# ECC_AGGR_ECC_AGGR_04703000h register map
Vendor: Texas Instruments
Peripheral module from a debugger description file (folder am62D).
Registers are 32-bit, access not given, reset 0x0 unless marked. A register's access mark holds for its fields unless they carry their own. Offsets are as the file gives them; lines under a group give offsets from that group; [hi:lo] are bit positions; {n}, {i} and the like mark numbered series; 'fields as' and 'values as' point back to an identical list; <NAME> marks a mode.

## ecc_aggr
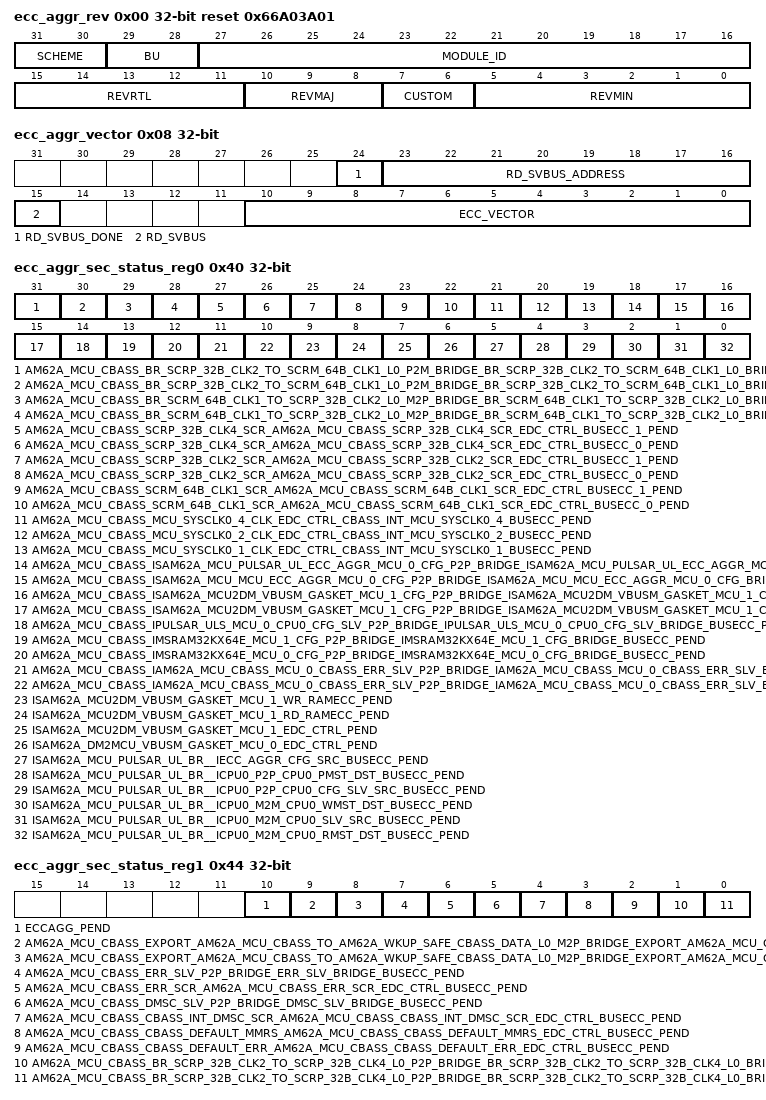
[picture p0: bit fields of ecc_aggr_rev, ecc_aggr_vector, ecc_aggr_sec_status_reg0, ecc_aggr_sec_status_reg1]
0x00 ecc_aggr_rev ro reset 0x66A03A01 — Revision parameters
  [31:30] SCHEME
  [29:28] BU
  [27:16] MODULE_ID
  [15:11] REVRTL — RTL version
  [10:8] REVMAJ — Major version
  [7:6] CUSTOM — Custom version
  [5:0] REVMIN — Minor version
0x08 ecc_aggr_vector — ECC Vector Register
  [24] RD_SVBUS_DONE — Status to indicate if read on serial VBUS is complete, write of any value will clear this bit. (access R/W1TC)
  [23:16] RD_SVBUS_ADDRESS rw — Read address
  [15] RD_SVBUS — Write 1 to trigger a read on the serial VBUS (access R/W1TS)
  [10:0] ECC_VECTOR rw — Value written to select the corresponding ECC RAM for control or status
0x0C ecc_aggr_stat ro reset 0x2B — Misc Status
  [10:0] NUM_RAMS — Indicates the number of RAMS serviced by the ECC aggregator
0x10 ecc_aggr_reserved_svbus_j rw — Reference other documents that contain the ECC RAM wrapper and EDC controller serial vbus register sets.
  [31:0] DATA — Serial VBUS register data
0x3C ecc_aggr_sec_eoi_reg — EOI Register
  [0] EOI_WR — EOI Register (access R/W1TS)
0x40 ecc_aggr_sec_status_reg0 — Interrupt Status Register 0
  [31] AM62A_MCU_CBASS_BR_SCRP_32B_CLK2_TO_SCRM_64B_CLK1_L0_P2M_BRIDGE_BR_SCRP_32B_CLK2_TO_SCRM_64B_CLK1_L0_BRIDGE_SRC_BUSECC_PEND — Interrupt Pending Status for am62a_mcu_cbass_br_SCRP_32b_clk2_to_SCRM_64b_clk1_l0_p2m_bridge_br_SCRP_32b_clk2_to_SCRM_64b_clk1_l0_bridge_src_busecc_pend (access R/W1TS)
  [30] AM62A_MCU_CBASS_BR_SCRP_32B_CLK2_TO_SCRM_64B_CLK1_L0_P2M_BRIDGE_BR_SCRP_32B_CLK2_TO_SCRM_64B_CLK1_L0_BRIDGE_DST_BUSECC_PEND — Interrupt Pending Status for am62a_mcu_cbass_br_SCRP_32b_clk2_to_SCRM_64b_clk1_l0_p2m_bridge_br_SCRP_32b_clk2_to_SCRM_64b_clk1_l0_bridge_dst_busecc_pend (access R/W1TS)
  [29] AM62A_MCU_CBASS_BR_SCRM_64B_CLK1_TO_SCRP_32B_CLK2_L0_M2P_BRIDGE_BR_SCRM_64B_CLK1_TO_SCRP_32B_CLK2_L0_BRIDGE_SRC_BUSECC_PEND — Interrupt Pending Status for am62a_mcu_cbass_br_SCRM_64b_clk1_to_SCRP_32b_clk2_l0_m2p_bridge_br_SCRM_64b_clk1_to_SCRP_32b_clk2_l0_bridge_src_busecc_pend (access R/W1TS)
  [28] AM62A_MCU_CBASS_BR_SCRM_64B_CLK1_TO_SCRP_32B_CLK2_L0_M2P_BRIDGE_BR_SCRM_64B_CLK1_TO_SCRP_32B_CLK2_L0_BRIDGE_DST_BUSECC_PEND — Interrupt Pending Status for am62a_mcu_cbass_br_SCRM_64b_clk1_to_SCRP_32b_clk2_l0_m2p_bridge_br_SCRM_64b_clk1_to_SCRP_32b_clk2_l0_bridge_dst_busecc_pend (access R/W1TS)
  [27] AM62A_MCU_CBASS_SCRP_32B_CLK4_SCR_AM62A_MCU_CBASS_SCRP_32B_CLK4_SCR_EDC_CTRL_BUSECC_1_PEND — Interrupt Pending Status for am62a_mcu_cbass_SCRP_32b_clk4_scr_am62a_mcu_cbass_SCRP_32b_clk4_scr_edc_ctrl_busecc_1_pend (access R/W1TS)
  [26] AM62A_MCU_CBASS_SCRP_32B_CLK4_SCR_AM62A_MCU_CBASS_SCRP_32B_CLK4_SCR_EDC_CTRL_BUSECC_0_PEND — Interrupt Pending Status for am62a_mcu_cbass_SCRP_32b_clk4_scr_am62a_mcu_cbass_SCRP_32b_clk4_scr_edc_ctrl_busecc_0_pend (access R/W1TS)
  [25] AM62A_MCU_CBASS_SCRP_32B_CLK2_SCR_AM62A_MCU_CBASS_SCRP_32B_CLK2_SCR_EDC_CTRL_BUSECC_1_PEND — Interrupt Pending Status for am62a_mcu_cbass_SCRP_32b_clk2_scr_am62a_mcu_cbass_SCRP_32b_clk2_scr_edc_ctrl_busecc_1_pend (access R/W1TS)
  [24] AM62A_MCU_CBASS_SCRP_32B_CLK2_SCR_AM62A_MCU_CBASS_SCRP_32B_CLK2_SCR_EDC_CTRL_BUSECC_0_PEND — Interrupt Pending Status for am62a_mcu_cbass_SCRP_32b_clk2_scr_am62a_mcu_cbass_SCRP_32b_clk2_scr_edc_ctrl_busecc_0_pend (access R/W1TS)
  [23] AM62A_MCU_CBASS_SCRM_64B_CLK1_SCR_AM62A_MCU_CBASS_SCRM_64B_CLK1_SCR_EDC_CTRL_BUSECC_1_PEND — Interrupt Pending Status for am62a_mcu_cbass_SCRM_64b_clk1_scr_am62a_mcu_cbass_SCRM_64b_clk1_scr_edc_ctrl_busecc_1_pend (access R/W1TS)
  [22] AM62A_MCU_CBASS_SCRM_64B_CLK1_SCR_AM62A_MCU_CBASS_SCRM_64B_CLK1_SCR_EDC_CTRL_BUSECC_0_PEND — Interrupt Pending Status for am62a_mcu_cbass_SCRM_64b_clk1_scr_am62a_mcu_cbass_SCRM_64b_clk1_scr_edc_ctrl_busecc_0_pend (access R/W1TS)
  [21] AM62A_MCU_CBASS_MCU_SYSCLK0_4_CLK_EDC_CTRL_CBASS_INT_MCU_SYSCLK0_4_BUSECC_PEND — Interrupt Pending Status for am62a_mcu_cbass_MCU_SYSCLK0_4_clk_edc_ctrl_cbass_int_MCU_SYSCLK0_4_busecc_pend (access R/W1TS)
  [20] AM62A_MCU_CBASS_MCU_SYSCLK0_2_CLK_EDC_CTRL_CBASS_INT_MCU_SYSCLK0_2_BUSECC_PEND — Interrupt Pending Status for am62a_mcu_cbass_MCU_SYSCLK0_2_clk_edc_ctrl_cbass_int_MCU_SYSCLK0_2_busecc_pend (access R/W1TS)
  [19] AM62A_MCU_CBASS_MCU_SYSCLK0_1_CLK_EDC_CTRL_CBASS_INT_MCU_SYSCLK0_1_BUSECC_PEND — Interrupt Pending Status for am62a_mcu_cbass_MCU_SYSCLK0_1_clk_edc_ctrl_cbass_int_MCU_SYSCLK0_1_busecc_pend (access R/W1TS)
  [18] AM62A_MCU_CBASS_ISAM62A_MCU_PULSAR_UL_ECC_AGGR_MCU_0_CFG_P2P_BRIDGE_ISAM62A_MCU_PULSAR_UL_ECC_AGGR_MCU_0_CFG_BRIDGE_BUSECC_PEND — Interrupt Pending Status for am62a_mcu_cbass_Isam62a_mcu_pulsar_ul_ecc_aggr_mcu_0_cfg_p2p_bridge_Isam62a_mcu_pulsar_ul_ecc_aggr_mcu_0_cfg_bridge_busecc_pend (access R/W1TS)
  [17] AM62A_MCU_CBASS_ISAM62A_MCU_MCU_ECC_AGGR_MCU_0_CFG_P2P_BRIDGE_ISAM62A_MCU_MCU_ECC_AGGR_MCU_0_CFG_BRIDGE_BUSECC_PEND — Interrupt Pending Status for am62a_mcu_cbass_Isam62a_mcu_mcu_ecc_aggr_mcu_0_cfg_p2p_bridge_Isam62a_mcu_mcu_ecc_aggr_mcu_0_cfg_bridge_busecc_pend (access R/W1TS)
  [16] AM62A_MCU_CBASS_ISAM62A_MCU2DM_VBUSM_GASKET_MCU_1_CFG_P2P_BRIDGE_ISAM62A_MCU2DM_VBUSM_GASKET_MCU_1_CFG_BRIDGE_SRC_BUSECC_PEND — Interrupt Pending Status for am62a_mcu_cbass_Isam62a_mcu2dm_vbusm_gasket_mcu_1_cfg_p2p_bridge_Isam62a_mcu2dm_vbusm_gasket_mcu_1_cfg_bridge_src_busecc_pend (access R/W1TS)
  [15] AM62A_MCU_CBASS_ISAM62A_MCU2DM_VBUSM_GASKET_MCU_1_CFG_P2P_BRIDGE_ISAM62A_MCU2DM_VBUSM_GASKET_MCU_1_CFG_BRIDGE_DST_BUSECC_PEND — Interrupt Pending Status for am62a_mcu_cbass_Isam62a_mcu2dm_vbusm_gasket_mcu_1_cfg_p2p_bridge_Isam62a_mcu2dm_vbusm_gasket_mcu_1_cfg_bridge_dst_busecc_pend (access R/W1TS)
  [14] AM62A_MCU_CBASS_IPULSAR_ULS_MCU_0_CPU0_CFG_SLV_P2P_BRIDGE_IPULSAR_ULS_MCU_0_CPU0_CFG_SLV_BRIDGE_BUSECC_PEND — Interrupt Pending Status for am62a_mcu_cbass_Ipulsar_uls_mcu_0_cpu0_cfg_slv_p2p_bridge_Ipulsar_uls_mcu_0_cpu0_cfg_slv_bridge_busecc_pend (access R/W1TS)
  [13] AM62A_MCU_CBASS_IMSRAM32KX64E_MCU_1_CFG_P2P_BRIDGE_IMSRAM32KX64E_MCU_1_CFG_BRIDGE_BUSECC_PEND — Interrupt Pending Status for am62a_mcu_cbass_Imsram32kx64e_mcu_1_cfg_p2p_bridge_Imsram32kx64e_mcu_1_cfg_bridge_busecc_pend (access R/W1TS)
  [12] AM62A_MCU_CBASS_IMSRAM32KX64E_MCU_0_CFG_P2P_BRIDGE_IMSRAM32KX64E_MCU_0_CFG_BRIDGE_BUSECC_PEND — Interrupt Pending Status for am62a_mcu_cbass_Imsram32kx64e_mcu_0_cfg_p2p_bridge_Imsram32kx64e_mcu_0_cfg_bridge_busecc_pend (access R/W1TS)
  [11] AM62A_MCU_CBASS_IAM62A_MCU_CBASS_MCU_0_CBASS_ERR_SLV_P2P_BRIDGE_IAM62A_MCU_CBASS_MCU_0_CBASS_ERR_SLV_BRIDGE_SRC_BUSECC_PEND — Interrupt Pending Status for am62a_mcu_cbass_Iam62a_mcu_cbass_mcu_0_cbass_err_slv_p2p_bridge_Iam62a_mcu_cbass_mcu_0_cbass_err_slv_bridge_src_busecc_pend (access R/W1TS)
  [10] AM62A_MCU_CBASS_IAM62A_MCU_CBASS_MCU_0_CBASS_ERR_SLV_P2P_BRIDGE_IAM62A_MCU_CBASS_MCU_0_CBASS_ERR_SLV_BRIDGE_DST_BUSECC_PEND — Interrupt Pending Status for am62a_mcu_cbass_Iam62a_mcu_cbass_mcu_0_cbass_err_slv_p2p_bridge_Iam62a_mcu_cbass_mcu_0_cbass_err_slv_bridge_dst_busecc_pend (access R/W1TS)
  [9] ISAM62A_MCU2DM_VBUSM_GASKET_MCU_1_WR_RAMECC_PEND — Interrupt Pending Status for Isam62a_mcu2dm_vbusm_gasket_mcu_1_wr_ramecc_pend (access R/W1TS)
  [8] ISAM62A_MCU2DM_VBUSM_GASKET_MCU_1_RD_RAMECC_PEND — Interrupt Pending Status for Isam62a_mcu2dm_vbusm_gasket_mcu_1_rd_ramecc_pend (access R/W1TS)
  [7] ISAM62A_MCU2DM_VBUSM_GASKET_MCU_1_EDC_CTRL_PEND — Interrupt Pending Status for Isam62a_mcu2dm_vbusm_gasket_mcu_1_edc_ctrl_pend (access R/W1TS)
  [6] ISAM62A_DM2MCU_VBUSM_GASKET_MCU_0_EDC_CTRL_PEND — Interrupt Pending Status for Isam62a_dm2mcu_vbusm_gasket_mcu_0_edc_ctrl_pend (access R/W1TS)
  [5] ISAM62A_MCU_PULSAR_UL_BR__IECC_AGGR_CFG_SRC_BUSECC_PEND — Interrupt Pending Status for Isam62a_mcu_pulsar_ul_br__Iecc_aggr_cfg_src_busecc_pend (access R/W1TS)
  [4] ISAM62A_MCU_PULSAR_UL_BR__ICPU0_P2P_CPU0_PMST_DST_BUSECC_PEND — Interrupt Pending Status for Isam62a_mcu_pulsar_ul_br__Icpu0_p2p_cpu0_pmst_dst_busecc_pend (access R/W1TS)
  [3] ISAM62A_MCU_PULSAR_UL_BR__ICPU0_P2P_CPU0_CFG_SLV_SRC_BUSECC_PEND — Interrupt Pending Status for Isam62a_mcu_pulsar_ul_br__Icpu0_p2p_cpu0_cfg_slv_src_busecc_pend (access R/W1TS)
  [2] ISAM62A_MCU_PULSAR_UL_BR__ICPU0_M2M_CPU0_WMST_DST_BUSECC_PEND — Interrupt Pending Status for Isam62a_mcu_pulsar_ul_br__Icpu0_m2m_cpu0_wmst_dst_busecc_pend (access R/W1TS)
  [1] ISAM62A_MCU_PULSAR_UL_BR__ICPU0_M2M_CPU0_SLV_SRC_BUSECC_PEND — Interrupt Pending Status for Isam62a_mcu_pulsar_ul_br__Icpu0_m2m_cpu0_slv_src_busecc_pend (access R/W1TS)
  [0] ISAM62A_MCU_PULSAR_UL_BR__ICPU0_M2M_CPU0_RMST_DST_BUSECC_PEND — Interrupt Pending Status for Isam62a_mcu_pulsar_ul_br__Icpu0_m2m_cpu0_rmst_dst_busecc_pend (access R/W1TS)
0x44 ecc_aggr_sec_status_reg1 — Interrupt Status Register 1
  [10] ECCAGG_PEND — Interrupt Pending Status for eccagg_pend (access R/W1TS)
  [9] AM62A_MCU_CBASS_EXPORT_AM62A_MCU_CBASS_TO_AM62A_WKUP_SAFE_CBASS_DATA_L0_M2P_BRIDGE_EXPORT_AM62A_MCU_CBASS_TO_AM62A_WKUP_SAFE_CBASS_DATA_L0_BRIDGE_SRC_BUSECC_PEND — Interrupt Pending Status for am62a_mcu_cbass_export_am62a_mcu_cbass_to_am62a_wkup_safe_cbass_data_l0_m2p_bridge_export_am62a_mcu_cbass_to_am62a_wkup_safe_cbass_data_l0_bridge_src_busecc_pend (access R/W1TS)
  [8] AM62A_MCU_CBASS_EXPORT_AM62A_MCU_CBASS_TO_AM62A_WKUP_SAFE_CBASS_DATA_L0_M2P_BRIDGE_EXPORT_AM62A_MCU_CBASS_TO_AM62A_WKUP_SAFE_CBASS_DATA_L0_BRIDGE_DST_BUSECC_PEND — Interrupt Pending Status for am62a_mcu_cbass_export_am62a_mcu_cbass_to_am62a_wkup_safe_cbass_data_l0_m2p_bridge_export_am62a_mcu_cbass_to_am62a_wkup_safe_cbass_data_l0_bridge_dst_busecc_pend (access R/W1TS)
  [7] AM62A_MCU_CBASS_ERR_SLV_P2P_BRIDGE_ERR_SLV_BRIDGE_BUSECC_PEND — Interrupt Pending Status for am62a_mcu_cbass_err_slv_p2p_bridge_err_slv_bridge_busecc_pend (access R/W1TS)
  [6] AM62A_MCU_CBASS_ERR_SCR_AM62A_MCU_CBASS_ERR_SCR_EDC_CTRL_BUSECC_PEND — Interrupt Pending Status for am62a_mcu_cbass_err_scr_am62a_mcu_cbass_err_scr_edc_ctrl_busecc_pend (access R/W1TS)
  [5] AM62A_MCU_CBASS_DMSC_SLV_P2P_BRIDGE_DMSC_SLV_BRIDGE_BUSECC_PEND — Interrupt Pending Status for am62a_mcu_cbass_dmsc_slv_p2p_bridge_dmsc_slv_bridge_busecc_pend (access R/W1TS)
  [4] AM62A_MCU_CBASS_CBASS_INT_DMSC_SCR_AM62A_MCU_CBASS_CBASS_INT_DMSC_SCR_EDC_CTRL_BUSECC_PEND — Interrupt Pending Status for am62a_mcu_cbass_cbass_int_dmsc_scr_am62a_mcu_cbass_cbass_int_dmsc_scr_edc_ctrl_busecc_pend (access R/W1TS)
  [3] AM62A_MCU_CBASS_CBASS_DEFAULT_MMRS_AM62A_MCU_CBASS_CBASS_DEFAULT_MMRS_EDC_CTRL_BUSECC_PEND — Interrupt Pending Status for am62a_mcu_cbass_cbass_default_mmrs_am62a_mcu_cbass_cbass_default_mmrs_edc_ctrl_busecc_pend (access R/W1TS)
  [2] AM62A_MCU_CBASS_CBASS_DEFAULT_ERR_AM62A_MCU_CBASS_CBASS_DEFAULT_ERR_EDC_CTRL_BUSECC_PEND — Interrupt Pending Status for am62a_mcu_cbass_cbass_default_err_am62a_mcu_cbass_cbass_default_err_edc_ctrl_busecc_pend (access R/W1TS)
  [1] AM62A_MCU_CBASS_BR_SCRP_32B_CLK2_TO_SCRP_32B_CLK4_L0_P2P_BRIDGE_BR_SCRP_32B_CLK2_TO_SCRP_32B_CLK4_L0_BRIDGE_SRC_BUSECC_PEND — Interrupt Pending Status for am62a_mcu_cbass_br_SCRP_32b_clk2_to_SCRP_32b_clk4_l0_p2p_bridge_br_SCRP_32b_clk2_to_SCRP_32b_clk4_l0_bridge_src_busecc_pend (access R/W1TS)
  [0] AM62A_MCU_CBASS_BR_SCRP_32B_CLK2_TO_SCRP_32B_CLK4_L0_P2P_BRIDGE_BR_SCRP_32B_CLK2_TO_SCRP_32B_CLK4_L0_BRIDGE_DST_BUSECC_PEND — Interrupt Pending Status for am62a_mcu_cbass_br_SCRP_32b_clk2_to_SCRP_32b_clk4_l0_p2p_bridge_br_SCRP_32b_clk2_to_SCRP_32b_clk4_l0_bridge_dst_busecc_pend (access R/W1TS)
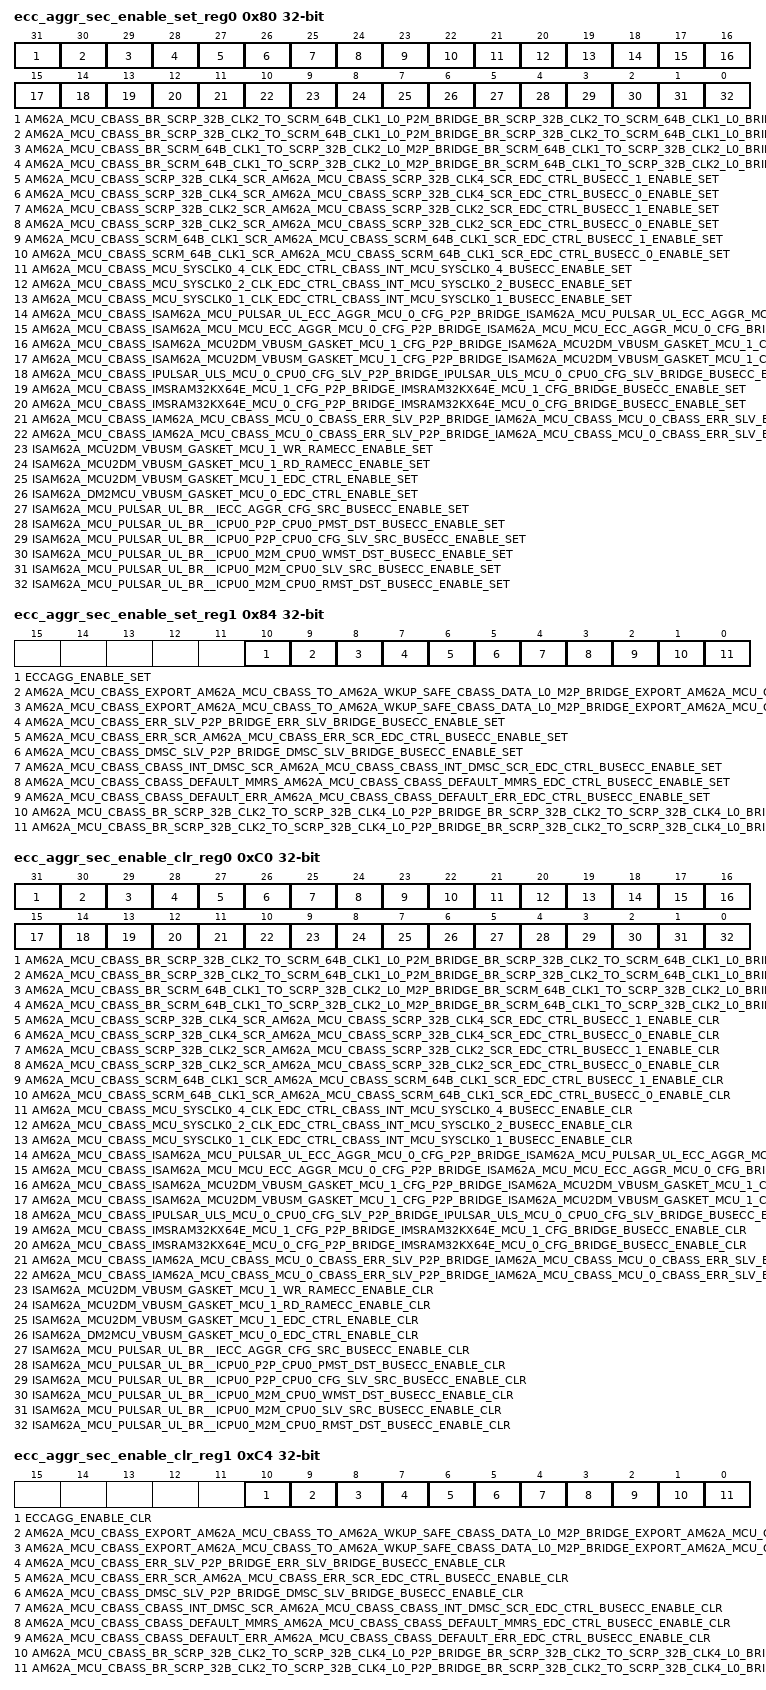
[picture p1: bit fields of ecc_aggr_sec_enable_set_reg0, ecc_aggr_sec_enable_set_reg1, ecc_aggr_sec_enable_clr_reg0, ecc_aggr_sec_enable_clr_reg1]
0x80 ecc_aggr_sec_enable_set_reg0 — Interrupt Enable Set Register 0
  [31] AM62A_MCU_CBASS_BR_SCRP_32B_CLK2_TO_SCRM_64B_CLK1_L0_P2M_BRIDGE_BR_SCRP_32B_CLK2_TO_SCRM_64B_CLK1_L0_BRIDGE_SRC_BUSECC_ENABLE_SET — Interrupt Enable Set Register for am62a_mcu_cbass_br_SCRP_32b_clk2_to_SCRM_64b_clk1_l0_p2m_bridge_br_SCRP_32b_clk2_to_SCRM_64b_clk1_l0_bridge_src_busecc_pend (access R/W1TS)
  [30] AM62A_MCU_CBASS_BR_SCRP_32B_CLK2_TO_SCRM_64B_CLK1_L0_P2M_BRIDGE_BR_SCRP_32B_CLK2_TO_SCRM_64B_CLK1_L0_BRIDGE_DST_BUSECC_ENABLE_SET — Interrupt Enable Set Register for am62a_mcu_cbass_br_SCRP_32b_clk2_to_SCRM_64b_clk1_l0_p2m_bridge_br_SCRP_32b_clk2_to_SCRM_64b_clk1_l0_bridge_dst_busecc_pend (access R/W1TS)
  [29] AM62A_MCU_CBASS_BR_SCRM_64B_CLK1_TO_SCRP_32B_CLK2_L0_M2P_BRIDGE_BR_SCRM_64B_CLK1_TO_SCRP_32B_CLK2_L0_BRIDGE_SRC_BUSECC_ENABLE_SET — Interrupt Enable Set Register for am62a_mcu_cbass_br_SCRM_64b_clk1_to_SCRP_32b_clk2_l0_m2p_bridge_br_SCRM_64b_clk1_to_SCRP_32b_clk2_l0_bridge_src_busecc_pend (access R/W1TS)
  [28] AM62A_MCU_CBASS_BR_SCRM_64B_CLK1_TO_SCRP_32B_CLK2_L0_M2P_BRIDGE_BR_SCRM_64B_CLK1_TO_SCRP_32B_CLK2_L0_BRIDGE_DST_BUSECC_ENABLE_SET — Interrupt Enable Set Register for am62a_mcu_cbass_br_SCRM_64b_clk1_to_SCRP_32b_clk2_l0_m2p_bridge_br_SCRM_64b_clk1_to_SCRP_32b_clk2_l0_bridge_dst_busecc_pend (access R/W1TS)
  [27] AM62A_MCU_CBASS_SCRP_32B_CLK4_SCR_AM62A_MCU_CBASS_SCRP_32B_CLK4_SCR_EDC_CTRL_BUSECC_1_ENABLE_SET — Interrupt Enable Set Register for am62a_mcu_cbass_SCRP_32b_clk4_scr_am62a_mcu_cbass_SCRP_32b_clk4_scr_edc_ctrl_busecc_1_pend (access R/W1TS)
  [26] AM62A_MCU_CBASS_SCRP_32B_CLK4_SCR_AM62A_MCU_CBASS_SCRP_32B_CLK4_SCR_EDC_CTRL_BUSECC_0_ENABLE_SET — Interrupt Enable Set Register for am62a_mcu_cbass_SCRP_32b_clk4_scr_am62a_mcu_cbass_SCRP_32b_clk4_scr_edc_ctrl_busecc_0_pend (access R/W1TS)
  [25] AM62A_MCU_CBASS_SCRP_32B_CLK2_SCR_AM62A_MCU_CBASS_SCRP_32B_CLK2_SCR_EDC_CTRL_BUSECC_1_ENABLE_SET — Interrupt Enable Set Register for am62a_mcu_cbass_SCRP_32b_clk2_scr_am62a_mcu_cbass_SCRP_32b_clk2_scr_edc_ctrl_busecc_1_pend (access R/W1TS)
  [24] AM62A_MCU_CBASS_SCRP_32B_CLK2_SCR_AM62A_MCU_CBASS_SCRP_32B_CLK2_SCR_EDC_CTRL_BUSECC_0_ENABLE_SET — Interrupt Enable Set Register for am62a_mcu_cbass_SCRP_32b_clk2_scr_am62a_mcu_cbass_SCRP_32b_clk2_scr_edc_ctrl_busecc_0_pend (access R/W1TS)
  [23] AM62A_MCU_CBASS_SCRM_64B_CLK1_SCR_AM62A_MCU_CBASS_SCRM_64B_CLK1_SCR_EDC_CTRL_BUSECC_1_ENABLE_SET — Interrupt Enable Set Register for am62a_mcu_cbass_SCRM_64b_clk1_scr_am62a_mcu_cbass_SCRM_64b_clk1_scr_edc_ctrl_busecc_1_pend (access R/W1TS)
  [22] AM62A_MCU_CBASS_SCRM_64B_CLK1_SCR_AM62A_MCU_CBASS_SCRM_64B_CLK1_SCR_EDC_CTRL_BUSECC_0_ENABLE_SET — Interrupt Enable Set Register for am62a_mcu_cbass_SCRM_64b_clk1_scr_am62a_mcu_cbass_SCRM_64b_clk1_scr_edc_ctrl_busecc_0_pend (access R/W1TS)
  [21] AM62A_MCU_CBASS_MCU_SYSCLK0_4_CLK_EDC_CTRL_CBASS_INT_MCU_SYSCLK0_4_BUSECC_ENABLE_SET — Interrupt Enable Set Register for am62a_mcu_cbass_MCU_SYSCLK0_4_clk_edc_ctrl_cbass_int_MCU_SYSCLK0_4_busecc_pend (access R/W1TS)
  [20] AM62A_MCU_CBASS_MCU_SYSCLK0_2_CLK_EDC_CTRL_CBASS_INT_MCU_SYSCLK0_2_BUSECC_ENABLE_SET — Interrupt Enable Set Register for am62a_mcu_cbass_MCU_SYSCLK0_2_clk_edc_ctrl_cbass_int_MCU_SYSCLK0_2_busecc_pend (access R/W1TS)
  [19] AM62A_MCU_CBASS_MCU_SYSCLK0_1_CLK_EDC_CTRL_CBASS_INT_MCU_SYSCLK0_1_BUSECC_ENABLE_SET — Interrupt Enable Set Register for am62a_mcu_cbass_MCU_SYSCLK0_1_clk_edc_ctrl_cbass_int_MCU_SYSCLK0_1_busecc_pend (access R/W1TS)
  [18] AM62A_MCU_CBASS_ISAM62A_MCU_PULSAR_UL_ECC_AGGR_MCU_0_CFG_P2P_BRIDGE_ISAM62A_MCU_PULSAR_UL_ECC_AGGR_MCU_0_CFG_BRIDGE_BUSECC_ENABLE_SET — Interrupt Enable Set Register for am62a_mcu_cbass_Isam62a_mcu_pulsar_ul_ecc_aggr_mcu_0_cfg_p2p_bridge_Isam62a_mcu_pulsar_ul_ecc_aggr_mcu_0_cfg_bridge_busecc_pend (access R/W1TS)
  [17] AM62A_MCU_CBASS_ISAM62A_MCU_MCU_ECC_AGGR_MCU_0_CFG_P2P_BRIDGE_ISAM62A_MCU_MCU_ECC_AGGR_MCU_0_CFG_BRIDGE_BUSECC_ENABLE_SET — Interrupt Enable Set Register for am62a_mcu_cbass_Isam62a_mcu_mcu_ecc_aggr_mcu_0_cfg_p2p_bridge_Isam62a_mcu_mcu_ecc_aggr_mcu_0_cfg_bridge_busecc_pend (access R/W1TS)
  [16] AM62A_MCU_CBASS_ISAM62A_MCU2DM_VBUSM_GASKET_MCU_1_CFG_P2P_BRIDGE_ISAM62A_MCU2DM_VBUSM_GASKET_MCU_1_CFG_BRIDGE_SRC_BUSECC_ENABLE_SET — Interrupt Enable Set Register for am62a_mcu_cbass_Isam62a_mcu2dm_vbusm_gasket_mcu_1_cfg_p2p_bridge_Isam62a_mcu2dm_vbusm_gasket_mcu_1_cfg_bridge_src_busecc_pend (access R/W1TS)
  [15] AM62A_MCU_CBASS_ISAM62A_MCU2DM_VBUSM_GASKET_MCU_1_CFG_P2P_BRIDGE_ISAM62A_MCU2DM_VBUSM_GASKET_MCU_1_CFG_BRIDGE_DST_BUSECC_ENABLE_SET — Interrupt Enable Set Register for am62a_mcu_cbass_Isam62a_mcu2dm_vbusm_gasket_mcu_1_cfg_p2p_bridge_Isam62a_mcu2dm_vbusm_gasket_mcu_1_cfg_bridge_dst_busecc_pend (access R/W1TS)
  [14] AM62A_MCU_CBASS_IPULSAR_ULS_MCU_0_CPU0_CFG_SLV_P2P_BRIDGE_IPULSAR_ULS_MCU_0_CPU0_CFG_SLV_BRIDGE_BUSECC_ENABLE_SET — Interrupt Enable Set Register for am62a_mcu_cbass_Ipulsar_uls_mcu_0_cpu0_cfg_slv_p2p_bridge_Ipulsar_uls_mcu_0_cpu0_cfg_slv_bridge_busecc_pend (access R/W1TS)
  [13] AM62A_MCU_CBASS_IMSRAM32KX64E_MCU_1_CFG_P2P_BRIDGE_IMSRAM32KX64E_MCU_1_CFG_BRIDGE_BUSECC_ENABLE_SET — Interrupt Enable Set Register for am62a_mcu_cbass_Imsram32kx64e_mcu_1_cfg_p2p_bridge_Imsram32kx64e_mcu_1_cfg_bridge_busecc_pend (access R/W1TS)
  [12] AM62A_MCU_CBASS_IMSRAM32KX64E_MCU_0_CFG_P2P_BRIDGE_IMSRAM32KX64E_MCU_0_CFG_BRIDGE_BUSECC_ENABLE_SET — Interrupt Enable Set Register for am62a_mcu_cbass_Imsram32kx64e_mcu_0_cfg_p2p_bridge_Imsram32kx64e_mcu_0_cfg_bridge_busecc_pend (access R/W1TS)
  [11] AM62A_MCU_CBASS_IAM62A_MCU_CBASS_MCU_0_CBASS_ERR_SLV_P2P_BRIDGE_IAM62A_MCU_CBASS_MCU_0_CBASS_ERR_SLV_BRIDGE_SRC_BUSECC_ENABLE_SET — Interrupt Enable Set Register for am62a_mcu_cbass_Iam62a_mcu_cbass_mcu_0_cbass_err_slv_p2p_bridge_Iam62a_mcu_cbass_mcu_0_cbass_err_slv_bridge_src_busecc_pend (access R/W1TS)
  [10] AM62A_MCU_CBASS_IAM62A_MCU_CBASS_MCU_0_CBASS_ERR_SLV_P2P_BRIDGE_IAM62A_MCU_CBASS_MCU_0_CBASS_ERR_SLV_BRIDGE_DST_BUSECC_ENABLE_SET — Interrupt Enable Set Register for am62a_mcu_cbass_Iam62a_mcu_cbass_mcu_0_cbass_err_slv_p2p_bridge_Iam62a_mcu_cbass_mcu_0_cbass_err_slv_bridge_dst_busecc_pend (access R/W1TS)
  [9] ISAM62A_MCU2DM_VBUSM_GASKET_MCU_1_WR_RAMECC_ENABLE_SET — Interrupt Enable Set Register for Isam62a_mcu2dm_vbusm_gasket_mcu_1_wr_ramecc_pend (access R/W1TS)
  [8] ISAM62A_MCU2DM_VBUSM_GASKET_MCU_1_RD_RAMECC_ENABLE_SET — Interrupt Enable Set Register for Isam62a_mcu2dm_vbusm_gasket_mcu_1_rd_ramecc_pend (access R/W1TS)
  [7] ISAM62A_MCU2DM_VBUSM_GASKET_MCU_1_EDC_CTRL_ENABLE_SET — Interrupt Enable Set Register for Isam62a_mcu2dm_vbusm_gasket_mcu_1_edc_ctrl_pend (access R/W1TS)
  [6] ISAM62A_DM2MCU_VBUSM_GASKET_MCU_0_EDC_CTRL_ENABLE_SET — Interrupt Enable Set Register for Isam62a_dm2mcu_vbusm_gasket_mcu_0_edc_ctrl_pend (access R/W1TS)
  [5] ISAM62A_MCU_PULSAR_UL_BR__IECC_AGGR_CFG_SRC_BUSECC_ENABLE_SET — Interrupt Enable Set Register for Isam62a_mcu_pulsar_ul_br__Iecc_aggr_cfg_src_busecc_pend (access R/W1TS)
  [4] ISAM62A_MCU_PULSAR_UL_BR__ICPU0_P2P_CPU0_PMST_DST_BUSECC_ENABLE_SET — Interrupt Enable Set Register for Isam62a_mcu_pulsar_ul_br__Icpu0_p2p_cpu0_pmst_dst_busecc_pend (access R/W1TS)
  [3] ISAM62A_MCU_PULSAR_UL_BR__ICPU0_P2P_CPU0_CFG_SLV_SRC_BUSECC_ENABLE_SET — Interrupt Enable Set Register for Isam62a_mcu_pulsar_ul_br__Icpu0_p2p_cpu0_cfg_slv_src_busecc_pend (access R/W1TS)
  [2] ISAM62A_MCU_PULSAR_UL_BR__ICPU0_M2M_CPU0_WMST_DST_BUSECC_ENABLE_SET — Interrupt Enable Set Register for Isam62a_mcu_pulsar_ul_br__Icpu0_m2m_cpu0_wmst_dst_busecc_pend (access R/W1TS)
  [1] ISAM62A_MCU_PULSAR_UL_BR__ICPU0_M2M_CPU0_SLV_SRC_BUSECC_ENABLE_SET — Interrupt Enable Set Register for Isam62a_mcu_pulsar_ul_br__Icpu0_m2m_cpu0_slv_src_busecc_pend (access R/W1TS)
  [0] ISAM62A_MCU_PULSAR_UL_BR__ICPU0_M2M_CPU0_RMST_DST_BUSECC_ENABLE_SET — Interrupt Enable Set Register for Isam62a_mcu_pulsar_ul_br__Icpu0_m2m_cpu0_rmst_dst_busecc_pend (access R/W1TS)
0x84 ecc_aggr_sec_enable_set_reg1 — Interrupt Enable Set Register 1
  [10] ECCAGG_ENABLE_SET — Interrupt Enable Set Register for eccagg_pend (access R/W1TS)
  [9] AM62A_MCU_CBASS_EXPORT_AM62A_MCU_CBASS_TO_AM62A_WKUP_SAFE_CBASS_DATA_L0_M2P_BRIDGE_EXPORT_AM62A_MCU_CBASS_TO_AM62A_WKUP_SAFE_CBASS_DATA_L0_BRIDGE_SRC_BUSECC_ENABLE_SET — Interrupt Enable Set Register for am62a_mcu_cbass_export_am62a_mcu_cbass_to_am62a_wkup_safe_cbass_data_l0_m2p_bridge_export_am62a_mcu_cbass_to_am62a_wkup_safe_cbass_data_l0_bridge_src_busecc_pend (access R/W1TS)
  [8] AM62A_MCU_CBASS_EXPORT_AM62A_MCU_CBASS_TO_AM62A_WKUP_SAFE_CBASS_DATA_L0_M2P_BRIDGE_EXPORT_AM62A_MCU_CBASS_TO_AM62A_WKUP_SAFE_CBASS_DATA_L0_BRIDGE_DST_BUSECC_ENABLE_SET — Interrupt Enable Set Register for am62a_mcu_cbass_export_am62a_mcu_cbass_to_am62a_wkup_safe_cbass_data_l0_m2p_bridge_export_am62a_mcu_cbass_to_am62a_wkup_safe_cbass_data_l0_bridge_dst_busecc_pend (access R/W1TS)
  [7] AM62A_MCU_CBASS_ERR_SLV_P2P_BRIDGE_ERR_SLV_BRIDGE_BUSECC_ENABLE_SET — Interrupt Enable Set Register for am62a_mcu_cbass_err_slv_p2p_bridge_err_slv_bridge_busecc_pend (access R/W1TS)
  [6] AM62A_MCU_CBASS_ERR_SCR_AM62A_MCU_CBASS_ERR_SCR_EDC_CTRL_BUSECC_ENABLE_SET — Interrupt Enable Set Register for am62a_mcu_cbass_err_scr_am62a_mcu_cbass_err_scr_edc_ctrl_busecc_pend (access R/W1TS)
  [5] AM62A_MCU_CBASS_DMSC_SLV_P2P_BRIDGE_DMSC_SLV_BRIDGE_BUSECC_ENABLE_SET — Interrupt Enable Set Register for am62a_mcu_cbass_dmsc_slv_p2p_bridge_dmsc_slv_bridge_busecc_pend (access R/W1TS)
  [4] AM62A_MCU_CBASS_CBASS_INT_DMSC_SCR_AM62A_MCU_CBASS_CBASS_INT_DMSC_SCR_EDC_CTRL_BUSECC_ENABLE_SET — Interrupt Enable Set Register for am62a_mcu_cbass_cbass_int_dmsc_scr_am62a_mcu_cbass_cbass_int_dmsc_scr_edc_ctrl_busecc_pend (access R/W1TS)
  [3] AM62A_MCU_CBASS_CBASS_DEFAULT_MMRS_AM62A_MCU_CBASS_CBASS_DEFAULT_MMRS_EDC_CTRL_BUSECC_ENABLE_SET — Interrupt Enable Set Register for am62a_mcu_cbass_cbass_default_mmrs_am62a_mcu_cbass_cbass_default_mmrs_edc_ctrl_busecc_pend (access R/W1TS)
  [2] AM62A_MCU_CBASS_CBASS_DEFAULT_ERR_AM62A_MCU_CBASS_CBASS_DEFAULT_ERR_EDC_CTRL_BUSECC_ENABLE_SET — Interrupt Enable Set Register for am62a_mcu_cbass_cbass_default_err_am62a_mcu_cbass_cbass_default_err_edc_ctrl_busecc_pend (access R/W1TS)
  [1] AM62A_MCU_CBASS_BR_SCRP_32B_CLK2_TO_SCRP_32B_CLK4_L0_P2P_BRIDGE_BR_SCRP_32B_CLK2_TO_SCRP_32B_CLK4_L0_BRIDGE_SRC_BUSECC_ENABLE_SET — Interrupt Enable Set Register for am62a_mcu_cbass_br_SCRP_32b_clk2_to_SCRP_32b_clk4_l0_p2p_bridge_br_SCRP_32b_clk2_to_SCRP_32b_clk4_l0_bridge_src_busecc_pend (access R/W1TS)
  [0] AM62A_MCU_CBASS_BR_SCRP_32B_CLK2_TO_SCRP_32B_CLK4_L0_P2P_BRIDGE_BR_SCRP_32B_CLK2_TO_SCRP_32B_CLK4_L0_BRIDGE_DST_BUSECC_ENABLE_SET — Interrupt Enable Set Register for am62a_mcu_cbass_br_SCRP_32b_clk2_to_SCRP_32b_clk4_l0_p2p_bridge_br_SCRP_32b_clk2_to_SCRP_32b_clk4_l0_bridge_dst_busecc_pend (access R/W1TS)
0xC0 ecc_aggr_sec_enable_clr_reg0 — Interrupt Enable Clear Register 0
  [31] AM62A_MCU_CBASS_BR_SCRP_32B_CLK2_TO_SCRM_64B_CLK1_L0_P2M_BRIDGE_BR_SCRP_32B_CLK2_TO_SCRM_64B_CLK1_L0_BRIDGE_SRC_BUSECC_ENABLE_CLR — Interrupt Enable Clear Register for am62a_mcu_cbass_br_SCRP_32b_clk2_to_SCRM_64b_clk1_l0_p2m_bridge_br_SCRP_32b_clk2_to_SCRM_64b_clk1_l0_bridge_src_busecc_pend (access R/W1TC)
  [30] AM62A_MCU_CBASS_BR_SCRP_32B_CLK2_TO_SCRM_64B_CLK1_L0_P2M_BRIDGE_BR_SCRP_32B_CLK2_TO_SCRM_64B_CLK1_L0_BRIDGE_DST_BUSECC_ENABLE_CLR — Interrupt Enable Clear Register for am62a_mcu_cbass_br_SCRP_32b_clk2_to_SCRM_64b_clk1_l0_p2m_bridge_br_SCRP_32b_clk2_to_SCRM_64b_clk1_l0_bridge_dst_busecc_pend (access R/W1TC)
  [29] AM62A_MCU_CBASS_BR_SCRM_64B_CLK1_TO_SCRP_32B_CLK2_L0_M2P_BRIDGE_BR_SCRM_64B_CLK1_TO_SCRP_32B_CLK2_L0_BRIDGE_SRC_BUSECC_ENABLE_CLR — Interrupt Enable Clear Register for am62a_mcu_cbass_br_SCRM_64b_clk1_to_SCRP_32b_clk2_l0_m2p_bridge_br_SCRM_64b_clk1_to_SCRP_32b_clk2_l0_bridge_src_busecc_pend (access R/W1TC)
  [28] AM62A_MCU_CBASS_BR_SCRM_64B_CLK1_TO_SCRP_32B_CLK2_L0_M2P_BRIDGE_BR_SCRM_64B_CLK1_TO_SCRP_32B_CLK2_L0_BRIDGE_DST_BUSECC_ENABLE_CLR — Interrupt Enable Clear Register for am62a_mcu_cbass_br_SCRM_64b_clk1_to_SCRP_32b_clk2_l0_m2p_bridge_br_SCRM_64b_clk1_to_SCRP_32b_clk2_l0_bridge_dst_busecc_pend (access R/W1TC)
  [27] AM62A_MCU_CBASS_SCRP_32B_CLK4_SCR_AM62A_MCU_CBASS_SCRP_32B_CLK4_SCR_EDC_CTRL_BUSECC_1_ENABLE_CLR — Interrupt Enable Clear Register for am62a_mcu_cbass_SCRP_32b_clk4_scr_am62a_mcu_cbass_SCRP_32b_clk4_scr_edc_ctrl_busecc_1_pend (access R/W1TC)
  [26] AM62A_MCU_CBASS_SCRP_32B_CLK4_SCR_AM62A_MCU_CBASS_SCRP_32B_CLK4_SCR_EDC_CTRL_BUSECC_0_ENABLE_CLR — Interrupt Enable Clear Register for am62a_mcu_cbass_SCRP_32b_clk4_scr_am62a_mcu_cbass_SCRP_32b_clk4_scr_edc_ctrl_busecc_0_pend (access R/W1TC)
  [25] AM62A_MCU_CBASS_SCRP_32B_CLK2_SCR_AM62A_MCU_CBASS_SCRP_32B_CLK2_SCR_EDC_CTRL_BUSECC_1_ENABLE_CLR — Interrupt Enable Clear Register for am62a_mcu_cbass_SCRP_32b_clk2_scr_am62a_mcu_cbass_SCRP_32b_clk2_scr_edc_ctrl_busecc_1_pend (access R/W1TC)
  [24] AM62A_MCU_CBASS_SCRP_32B_CLK2_SCR_AM62A_MCU_CBASS_SCRP_32B_CLK2_SCR_EDC_CTRL_BUSECC_0_ENABLE_CLR — Interrupt Enable Clear Register for am62a_mcu_cbass_SCRP_32b_clk2_scr_am62a_mcu_cbass_SCRP_32b_clk2_scr_edc_ctrl_busecc_0_pend (access R/W1TC)
  [23] AM62A_MCU_CBASS_SCRM_64B_CLK1_SCR_AM62A_MCU_CBASS_SCRM_64B_CLK1_SCR_EDC_CTRL_BUSECC_1_ENABLE_CLR — Interrupt Enable Clear Register for am62a_mcu_cbass_SCRM_64b_clk1_scr_am62a_mcu_cbass_SCRM_64b_clk1_scr_edc_ctrl_busecc_1_pend (access R/W1TC)
  [22] AM62A_MCU_CBASS_SCRM_64B_CLK1_SCR_AM62A_MCU_CBASS_SCRM_64B_CLK1_SCR_EDC_CTRL_BUSECC_0_ENABLE_CLR — Interrupt Enable Clear Register for am62a_mcu_cbass_SCRM_64b_clk1_scr_am62a_mcu_cbass_SCRM_64b_clk1_scr_edc_ctrl_busecc_0_pend (access R/W1TC)
  [21] AM62A_MCU_CBASS_MCU_SYSCLK0_4_CLK_EDC_CTRL_CBASS_INT_MCU_SYSCLK0_4_BUSECC_ENABLE_CLR — Interrupt Enable Clear Register for am62a_mcu_cbass_MCU_SYSCLK0_4_clk_edc_ctrl_cbass_int_MCU_SYSCLK0_4_busecc_pend (access R/W1TC)
  [20] AM62A_MCU_CBASS_MCU_SYSCLK0_2_CLK_EDC_CTRL_CBASS_INT_MCU_SYSCLK0_2_BUSECC_ENABLE_CLR — Interrupt Enable Clear Register for am62a_mcu_cbass_MCU_SYSCLK0_2_clk_edc_ctrl_cbass_int_MCU_SYSCLK0_2_busecc_pend (access R/W1TC)
  [19] AM62A_MCU_CBASS_MCU_SYSCLK0_1_CLK_EDC_CTRL_CBASS_INT_MCU_SYSCLK0_1_BUSECC_ENABLE_CLR — Interrupt Enable Clear Register for am62a_mcu_cbass_MCU_SYSCLK0_1_clk_edc_ctrl_cbass_int_MCU_SYSCLK0_1_busecc_pend (access R/W1TC)
  [18] AM62A_MCU_CBASS_ISAM62A_MCU_PULSAR_UL_ECC_AGGR_MCU_0_CFG_P2P_BRIDGE_ISAM62A_MCU_PULSAR_UL_ECC_AGGR_MCU_0_CFG_BRIDGE_BUSECC_ENABLE_CLR — Interrupt Enable Clear Register for am62a_mcu_cbass_Isam62a_mcu_pulsar_ul_ecc_aggr_mcu_0_cfg_p2p_bridge_Isam62a_mcu_pulsar_ul_ecc_aggr_mcu_0_cfg_bridge_busecc_pend (access R/W1TC)
  [17] AM62A_MCU_CBASS_ISAM62A_MCU_MCU_ECC_AGGR_MCU_0_CFG_P2P_BRIDGE_ISAM62A_MCU_MCU_ECC_AGGR_MCU_0_CFG_BRIDGE_BUSECC_ENABLE_CLR — Interrupt Enable Clear Register for am62a_mcu_cbass_Isam62a_mcu_mcu_ecc_aggr_mcu_0_cfg_p2p_bridge_Isam62a_mcu_mcu_ecc_aggr_mcu_0_cfg_bridge_busecc_pend (access R/W1TC)
  [16] AM62A_MCU_CBASS_ISAM62A_MCU2DM_VBUSM_GASKET_MCU_1_CFG_P2P_BRIDGE_ISAM62A_MCU2DM_VBUSM_GASKET_MCU_1_CFG_BRIDGE_SRC_BUSECC_ENABLE_CLR — Interrupt Enable Clear Register for am62a_mcu_cbass_Isam62a_mcu2dm_vbusm_gasket_mcu_1_cfg_p2p_bridge_Isam62a_mcu2dm_vbusm_gasket_mcu_1_cfg_bridge_src_busecc_pend (access R/W1TC)
  [15] AM62A_MCU_CBASS_ISAM62A_MCU2DM_VBUSM_GASKET_MCU_1_CFG_P2P_BRIDGE_ISAM62A_MCU2DM_VBUSM_GASKET_MCU_1_CFG_BRIDGE_DST_BUSECC_ENABLE_CLR — Interrupt Enable Clear Register for am62a_mcu_cbass_Isam62a_mcu2dm_vbusm_gasket_mcu_1_cfg_p2p_bridge_Isam62a_mcu2dm_vbusm_gasket_mcu_1_cfg_bridge_dst_busecc_pend (access R/W1TC)
  [14] AM62A_MCU_CBASS_IPULSAR_ULS_MCU_0_CPU0_CFG_SLV_P2P_BRIDGE_IPULSAR_ULS_MCU_0_CPU0_CFG_SLV_BRIDGE_BUSECC_ENABLE_CLR — Interrupt Enable Clear Register for am62a_mcu_cbass_Ipulsar_uls_mcu_0_cpu0_cfg_slv_p2p_bridge_Ipulsar_uls_mcu_0_cpu0_cfg_slv_bridge_busecc_pend (access R/W1TC)
  [13] AM62A_MCU_CBASS_IMSRAM32KX64E_MCU_1_CFG_P2P_BRIDGE_IMSRAM32KX64E_MCU_1_CFG_BRIDGE_BUSECC_ENABLE_CLR — Interrupt Enable Clear Register for am62a_mcu_cbass_Imsram32kx64e_mcu_1_cfg_p2p_bridge_Imsram32kx64e_mcu_1_cfg_bridge_busecc_pend (access R/W1TC)
  [12] AM62A_MCU_CBASS_IMSRAM32KX64E_MCU_0_CFG_P2P_BRIDGE_IMSRAM32KX64E_MCU_0_CFG_BRIDGE_BUSECC_ENABLE_CLR — Interrupt Enable Clear Register for am62a_mcu_cbass_Imsram32kx64e_mcu_0_cfg_p2p_bridge_Imsram32kx64e_mcu_0_cfg_bridge_busecc_pend (access R/W1TC)
  [11] AM62A_MCU_CBASS_IAM62A_MCU_CBASS_MCU_0_CBASS_ERR_SLV_P2P_BRIDGE_IAM62A_MCU_CBASS_MCU_0_CBASS_ERR_SLV_BRIDGE_SRC_BUSECC_ENABLE_CLR — Interrupt Enable Clear Register for am62a_mcu_cbass_Iam62a_mcu_cbass_mcu_0_cbass_err_slv_p2p_bridge_Iam62a_mcu_cbass_mcu_0_cbass_err_slv_bridge_src_busecc_pend (access R/W1TC)
  [10] AM62A_MCU_CBASS_IAM62A_MCU_CBASS_MCU_0_CBASS_ERR_SLV_P2P_BRIDGE_IAM62A_MCU_CBASS_MCU_0_CBASS_ERR_SLV_BRIDGE_DST_BUSECC_ENABLE_CLR — Interrupt Enable Clear Register for am62a_mcu_cbass_Iam62a_mcu_cbass_mcu_0_cbass_err_slv_p2p_bridge_Iam62a_mcu_cbass_mcu_0_cbass_err_slv_bridge_dst_busecc_pend (access R/W1TC)
  [9] ISAM62A_MCU2DM_VBUSM_GASKET_MCU_1_WR_RAMECC_ENABLE_CLR — Interrupt Enable Clear Register for Isam62a_mcu2dm_vbusm_gasket_mcu_1_wr_ramecc_pend (access R/W1TC)
  [8] ISAM62A_MCU2DM_VBUSM_GASKET_MCU_1_RD_RAMECC_ENABLE_CLR — Interrupt Enable Clear Register for Isam62a_mcu2dm_vbusm_gasket_mcu_1_rd_ramecc_pend (access R/W1TC)
  [7] ISAM62A_MCU2DM_VBUSM_GASKET_MCU_1_EDC_CTRL_ENABLE_CLR — Interrupt Enable Clear Register for Isam62a_mcu2dm_vbusm_gasket_mcu_1_edc_ctrl_pend (access R/W1TC)
  [6] ISAM62A_DM2MCU_VBUSM_GASKET_MCU_0_EDC_CTRL_ENABLE_CLR — Interrupt Enable Clear Register for Isam62a_dm2mcu_vbusm_gasket_mcu_0_edc_ctrl_pend (access R/W1TC)
  [5] ISAM62A_MCU_PULSAR_UL_BR__IECC_AGGR_CFG_SRC_BUSECC_ENABLE_CLR — Interrupt Enable Clear Register for Isam62a_mcu_pulsar_ul_br__Iecc_aggr_cfg_src_busecc_pend (access R/W1TC)
  [4] ISAM62A_MCU_PULSAR_UL_BR__ICPU0_P2P_CPU0_PMST_DST_BUSECC_ENABLE_CLR — Interrupt Enable Clear Register for Isam62a_mcu_pulsar_ul_br__Icpu0_p2p_cpu0_pmst_dst_busecc_pend (access R/W1TC)
  [3] ISAM62A_MCU_PULSAR_UL_BR__ICPU0_P2P_CPU0_CFG_SLV_SRC_BUSECC_ENABLE_CLR — Interrupt Enable Clear Register for Isam62a_mcu_pulsar_ul_br__Icpu0_p2p_cpu0_cfg_slv_src_busecc_pend (access R/W1TC)
  [2] ISAM62A_MCU_PULSAR_UL_BR__ICPU0_M2M_CPU0_WMST_DST_BUSECC_ENABLE_CLR — Interrupt Enable Clear Register for Isam62a_mcu_pulsar_ul_br__Icpu0_m2m_cpu0_wmst_dst_busecc_pend (access R/W1TC)
  [1] ISAM62A_MCU_PULSAR_UL_BR__ICPU0_M2M_CPU0_SLV_SRC_BUSECC_ENABLE_CLR — Interrupt Enable Clear Register for Isam62a_mcu_pulsar_ul_br__Icpu0_m2m_cpu0_slv_src_busecc_pend (access R/W1TC)
  [0] ISAM62A_MCU_PULSAR_UL_BR__ICPU0_M2M_CPU0_RMST_DST_BUSECC_ENABLE_CLR — Interrupt Enable Clear Register for Isam62a_mcu_pulsar_ul_br__Icpu0_m2m_cpu0_rmst_dst_busecc_pend (access R/W1TC)
0xC4 ecc_aggr_sec_enable_clr_reg1 — Interrupt Enable Clear Register 1
  [10] ECCAGG_ENABLE_CLR — Interrupt Enable Clear Register for eccagg_pend (access R/W1TC)
  [9] AM62A_MCU_CBASS_EXPORT_AM62A_MCU_CBASS_TO_AM62A_WKUP_SAFE_CBASS_DATA_L0_M2P_BRIDGE_EXPORT_AM62A_MCU_CBASS_TO_AM62A_WKUP_SAFE_CBASS_DATA_L0_BRIDGE_SRC_BUSECC_ENABLE_CLR — Interrupt Enable Clear Register for am62a_mcu_cbass_export_am62a_mcu_cbass_to_am62a_wkup_safe_cbass_data_l0_m2p_bridge_export_am62a_mcu_cbass_to_am62a_wkup_safe_cbass_data_l0_bridge_src_busecc_pend (access R/W1TC)
  [8] AM62A_MCU_CBASS_EXPORT_AM62A_MCU_CBASS_TO_AM62A_WKUP_SAFE_CBASS_DATA_L0_M2P_BRIDGE_EXPORT_AM62A_MCU_CBASS_TO_AM62A_WKUP_SAFE_CBASS_DATA_L0_BRIDGE_DST_BUSECC_ENABLE_CLR — Interrupt Enable Clear Register for am62a_mcu_cbass_export_am62a_mcu_cbass_to_am62a_wkup_safe_cbass_data_l0_m2p_bridge_export_am62a_mcu_cbass_to_am62a_wkup_safe_cbass_data_l0_bridge_dst_busecc_pend (access R/W1TC)
  [7] AM62A_MCU_CBASS_ERR_SLV_P2P_BRIDGE_ERR_SLV_BRIDGE_BUSECC_ENABLE_CLR — Interrupt Enable Clear Register for am62a_mcu_cbass_err_slv_p2p_bridge_err_slv_bridge_busecc_pend (access R/W1TC)
  [6] AM62A_MCU_CBASS_ERR_SCR_AM62A_MCU_CBASS_ERR_SCR_EDC_CTRL_BUSECC_ENABLE_CLR — Interrupt Enable Clear Register for am62a_mcu_cbass_err_scr_am62a_mcu_cbass_err_scr_edc_ctrl_busecc_pend (access R/W1TC)
  [5] AM62A_MCU_CBASS_DMSC_SLV_P2P_BRIDGE_DMSC_SLV_BRIDGE_BUSECC_ENABLE_CLR — Interrupt Enable Clear Register for am62a_mcu_cbass_dmsc_slv_p2p_bridge_dmsc_slv_bridge_busecc_pend (access R/W1TC)
  [4] AM62A_MCU_CBASS_CBASS_INT_DMSC_SCR_AM62A_MCU_CBASS_CBASS_INT_DMSC_SCR_EDC_CTRL_BUSECC_ENABLE_CLR — Interrupt Enable Clear Register for am62a_mcu_cbass_cbass_int_dmsc_scr_am62a_mcu_cbass_cbass_int_dmsc_scr_edc_ctrl_busecc_pend (access R/W1TC)
  [3] AM62A_MCU_CBASS_CBASS_DEFAULT_MMRS_AM62A_MCU_CBASS_CBASS_DEFAULT_MMRS_EDC_CTRL_BUSECC_ENABLE_CLR — Interrupt Enable Clear Register for am62a_mcu_cbass_cbass_default_mmrs_am62a_mcu_cbass_cbass_default_mmrs_edc_ctrl_busecc_pend (access R/W1TC)
  [2] AM62A_MCU_CBASS_CBASS_DEFAULT_ERR_AM62A_MCU_CBASS_CBASS_DEFAULT_ERR_EDC_CTRL_BUSECC_ENABLE_CLR — Interrupt Enable Clear Register for am62a_mcu_cbass_cbass_default_err_am62a_mcu_cbass_cbass_default_err_edc_ctrl_busecc_pend (access R/W1TC)
  [1] AM62A_MCU_CBASS_BR_SCRP_32B_CLK2_TO_SCRP_32B_CLK4_L0_P2P_BRIDGE_BR_SCRP_32B_CLK2_TO_SCRP_32B_CLK4_L0_BRIDGE_SRC_BUSECC_ENABLE_CLR — Interrupt Enable Clear Register for am62a_mcu_cbass_br_SCRP_32b_clk2_to_SCRP_32b_clk4_l0_p2p_bridge_br_SCRP_32b_clk2_to_SCRP_32b_clk4_l0_bridge_src_busecc_pend (access R/W1TC)
  [0] AM62A_MCU_CBASS_BR_SCRP_32B_CLK2_TO_SCRP_32B_CLK4_L0_P2P_BRIDGE_BR_SCRP_32B_CLK2_TO_SCRP_32B_CLK4_L0_BRIDGE_DST_BUSECC_ENABLE_CLR — Interrupt Enable Clear Register for am62a_mcu_cbass_br_SCRP_32b_clk2_to_SCRP_32b_clk4_l0_p2p_bridge_br_SCRP_32b_clk2_to_SCRP_32b_clk4_l0_bridge_dst_busecc_pend (access R/W1TC)
0x13C ecc_aggr_ded_eoi_reg — EOI Register
  [0] EOI_WR — EOI Register (access R/W1TS)
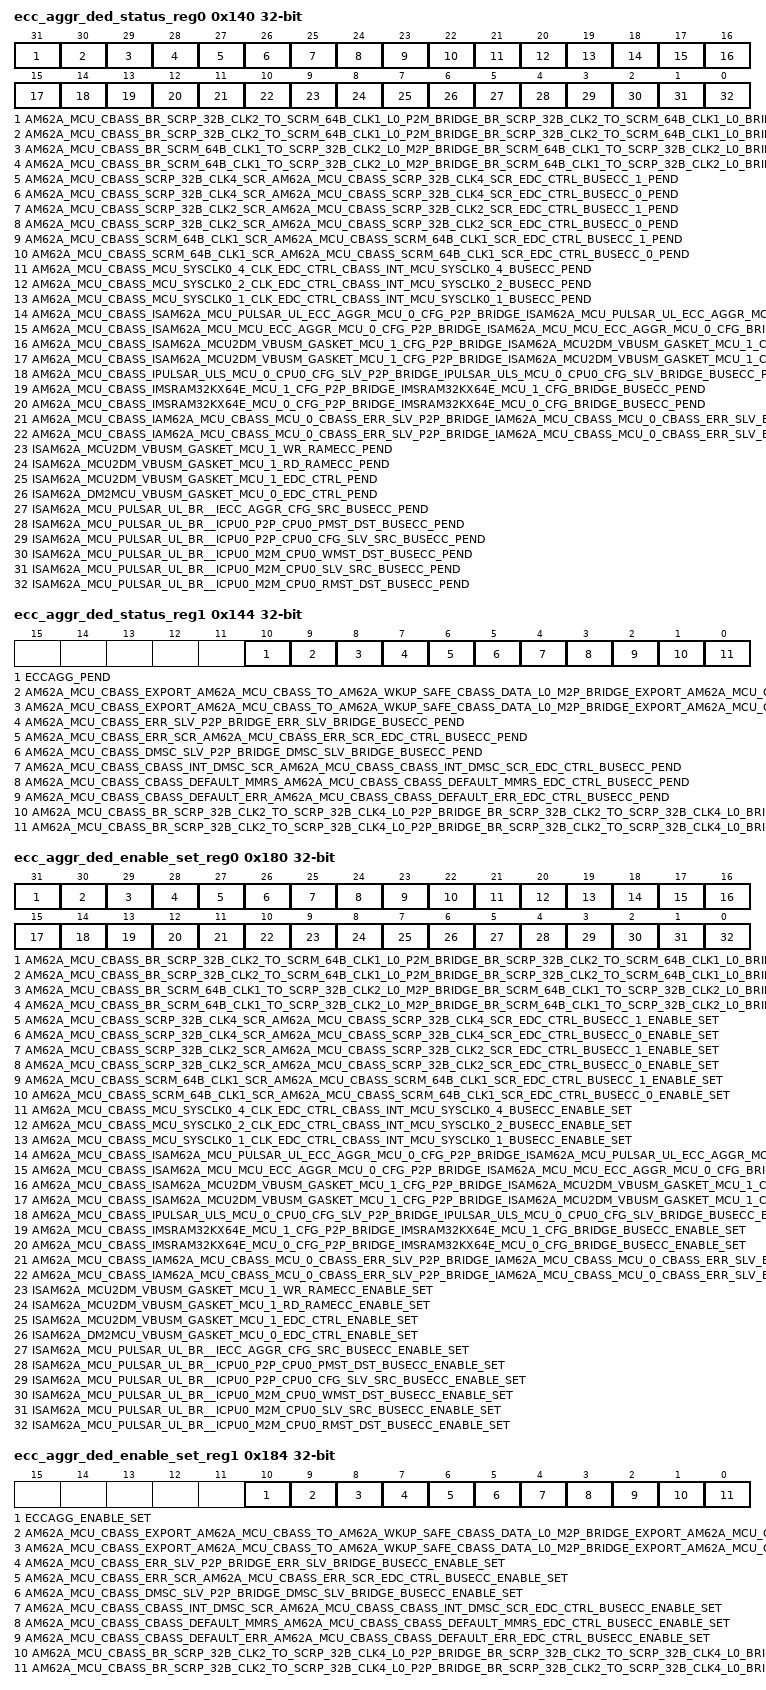
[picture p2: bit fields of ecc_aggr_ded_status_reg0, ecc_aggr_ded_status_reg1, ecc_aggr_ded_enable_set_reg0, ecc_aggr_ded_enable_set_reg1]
0x140 ecc_aggr_ded_status_reg0 — Interrupt Status Register 0
  fields as ecc_aggr_sec_status_reg0
0x144 ecc_aggr_ded_status_reg1 — Interrupt Status Register 1
  fields as ecc_aggr_sec_status_reg1
0x180 ecc_aggr_ded_enable_set_reg0 — Interrupt Enable Set Register 0
  fields as ecc_aggr_sec_enable_set_reg0
0x184 ecc_aggr_ded_enable_set_reg1 — Interrupt Enable Set Register 1
  fields as ecc_aggr_sec_enable_set_reg1
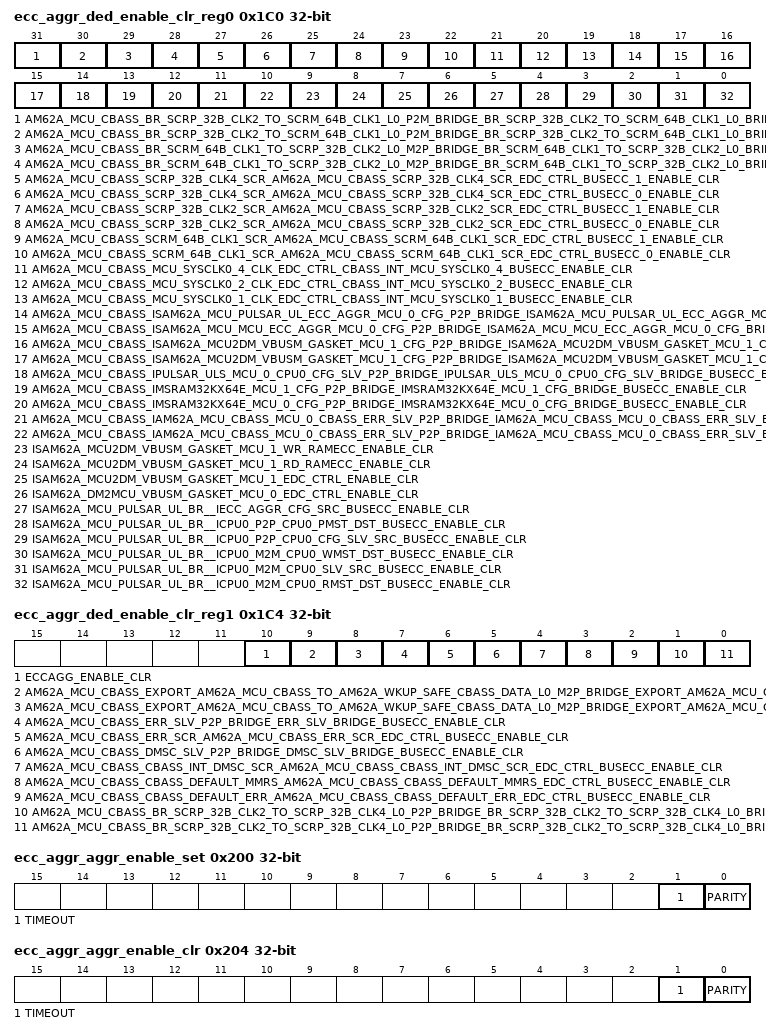
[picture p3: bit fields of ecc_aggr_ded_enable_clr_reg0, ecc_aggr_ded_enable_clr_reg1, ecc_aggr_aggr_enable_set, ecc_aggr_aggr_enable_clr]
0x1C0 ecc_aggr_ded_enable_clr_reg0 — Interrupt Enable Clear Register 0
  fields as ecc_aggr_sec_enable_clr_reg0
0x1C4 ecc_aggr_ded_enable_clr_reg1 — Interrupt Enable Clear Register 1
  fields as ecc_aggr_sec_enable_clr_reg1
0x200 ecc_aggr_aggr_enable_set — AGGR interrupt enable set Register
  [1] TIMEOUT — interrupt enable set for svbus timeout errors (access R/W1TS)
  [0] PARITY — interrupt enable set for parity errors (access R/W1TS)
0x204 ecc_aggr_aggr_enable_clr — AGGR interrupt enable clear Register
  [1] TIMEOUT — interrupt enable clear for svbus timeout errors (access R/W1TC)
  [0] PARITY — interrupt enable clear for parity errors (access R/W1TC)
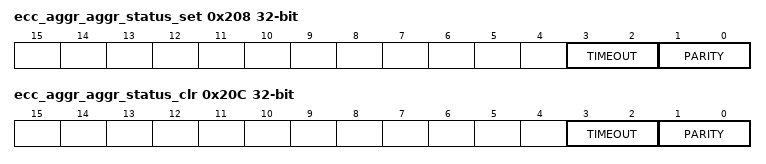
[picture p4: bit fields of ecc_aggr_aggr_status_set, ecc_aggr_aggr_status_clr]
0x208 ecc_aggr_aggr_status_set — AGGR interrupt status set Register
  [3:2] TIMEOUT — interrupt status set for svbus timeout errors (access R/WI)
  [1:0] PARITY — interrupt status set for parity errors (access R/WI)
0x20C ecc_aggr_aggr_status_clr — AGGR interrupt status clear Register
  [3:2] TIMEOUT — interrupt status clear for svbus timeout errors (access R/WD)
  [1:0] PARITY — interrupt status clear for parity errors (access R/WD)
